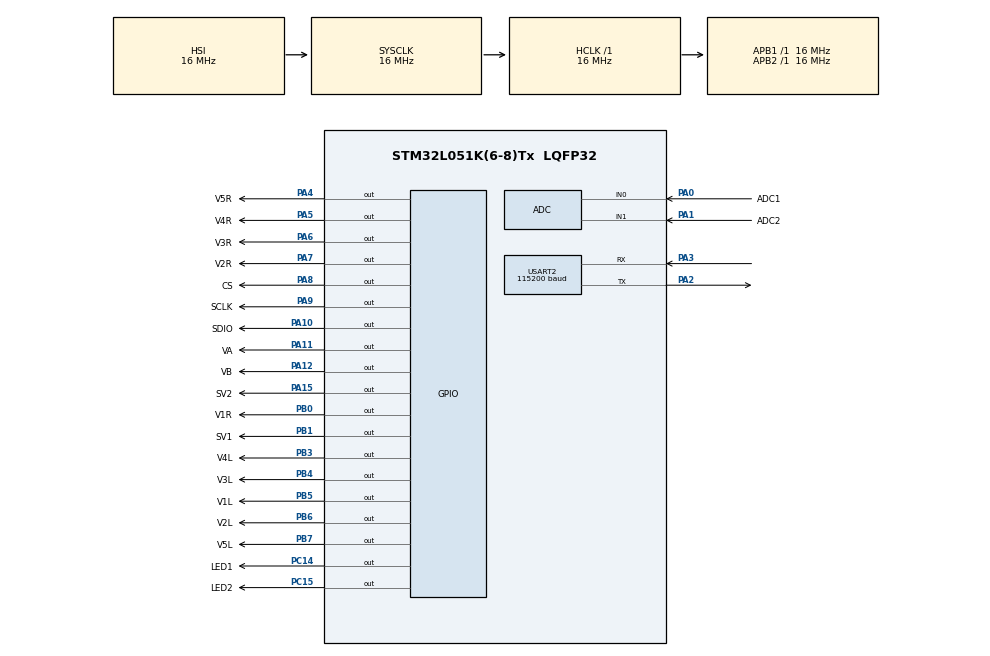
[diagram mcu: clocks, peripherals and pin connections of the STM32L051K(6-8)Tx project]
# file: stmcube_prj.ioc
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Mcu.Family=STM32L0
Mcu.Name=STM32L051K(6-8)Tx
Mcu.Package=LQFP32
NVIC.USART2_IRQn=true\:0\:0\:false\:false\:true\:true\:true
PA0.GPIO_Label=ADC1
PA0.Mode=IN0
PA0.Signal=ADC_IN0
PA1.GPIO_Label=ADC2
PA1.Mode=IN1
PA1.Signal=ADC_IN1
PA10.GPIO_Label=SDIO
PA10.Signal=GPIO_Output
PA11.GPIO_Label=VA
PA11.Signal=GPIO_Output
PA12.GPIO_Label=VB
PA12.Signal=GPIO_Output
PA13.Mode=Serial_Wire
PA13.Signal=SYS_SWDIO
PA14.Mode=Serial_Wire
PA14.Signal=SYS_SWCLK
PA15.GPIO_Label=SV2
PA15.Signal=GPIO_Output
PA2.Mode=Asynchronous
PA2.Signal=USART2_TX
PA3.Mode=Asynchronous
PA3.Signal=USART2_RX
PA4.GPIO_Label=V5R
PA4.Signal=GPIO_Output
PA5.GPIO_Label=V4R
PA5.Signal=GPIO_Output
PA6.GPIO_Label=V3R
PA6.Signal=GPIO_Output
PA7.GPIO_Label=V2R
PA7.Signal=GPIO_Output
PA8.GPIO_Label=CS
PA8.Signal=GPIO_Output
PA9.GPIO_Label=SCLK
PA9.Signal=GPIO_Output
PB0.GPIO_Label=V1R
PB0.Signal=GPIO_Output
PB1.GPIO_Label=SV1
PB1.Signal=GPIO_Output
PB3.GPIO_Label=V4L
PB3.Signal=GPIO_Output
PB4.GPIO_Label=V3L
PB4.Signal=GPIO_Output
PB5.GPIO_Label=V1L
PB5.Signal=GPIO_Output
PB6.GPIO_Label=V2L
PB6.Signal=GPIO_Output
PB7.GPIO_Label=V5L
PB7.Signal=GPIO_Output
PC14-OSC32_IN.GPIO_Label=LED1
PC14-OSC32_IN.Signal=GPIO_Output
PC15-OSC32_OUT.GPIO_Label=LED2
PC15-OSC32_OUT.Signal=GPIO_Output
ProjectManager.HeapSize=0x200
ProjectManager.StackSize=0x400
ProjectManager.TargetToolchain=TrueSTUDIO
RCC.AHBFreq_Value=16000000
RCC.APB1Freq_Value=16000000
RCC.APB1TimFreq_Value=16000000
RCC.APB2Freq_Value=16000000
RCC.APB2TimFreq_Value=16000000
RCC.HCLKFreq_Value=16000000
RCC.HSI16_VALUE=16000000
RCC.HSI_VALUE=16000000
RCC.LSE_VALUE=32768
RCC.MSI_VALUE=2097000
RCC.SYSCLKFreq_VALUE=16000000
RCC.SYSCLKSource=RCC_SYSCLKSOURCE_HSI
RCC.VCOOutputFreq_Value=48000000
USART2.BaudRate=115200
USART2.VirtualMode-Asynchronous=VM_ASYNC
board=custom

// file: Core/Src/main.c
/* USER CODE BEGIN Header */
/**
  ******************************************************************************
  * @file           : main.c
  * @brief          : Main program body
  ******************************************************************************
  * @attention
  *
  * <h2><center>&copy; Copyright (c) 2021 STMicroelectronics.
  * All rights reserved.</center></h2>
  *
  * This software component is licensed by ST under BSD 3-Clause license,
  * the "License"; You may not use this file except in compliance with the
  * License. You may obtain a copy of the License at:
  *                        opensource.org/licenses/BSD-3-Clause
  *
  ******************************************************************************
  */
/* USER CODE END Header */
#include "main.h"

/* USER CODE BEGIN PTD */
extern void handler_entry();
/* USER CODE END PTD */

ADC_HandleTypeDef hadc;

UART_HandleTypeDef huart2;

void SystemClock_Config(void);
static void MX_GPIO_Init(void);
static void MX_ADC_Init(void);
static void MX_USART2_UART_Init(void);

int main(void)
{

  /* MCU Configuration--------------------------------------------------------*/

  /* Reset of all peripherals, Initializes the Flash interface and the Systick. */
  HAL_Init();

  /* Configure the system clock */
  SystemClock_Config();

  /* Initialize all configured peripherals */
  MX_GPIO_Init();
  MX_ADC_Init();
  MX_USART2_UART_Init();

  /* Infinite loop */
  while (1)
  {

    /* USER CODE BEGIN 3 */
	  handler_entry();
  }
  /* USER CODE END 3 */
}

void SystemClock_Config(void)
{
  RCC_OscInitTypeDef RCC_OscInitStruct = {0};
  RCC_ClkInitTypeDef RCC_ClkInitStruct = {0};
  RCC_PeriphCLKInitTypeDef PeriphClkInit = {0};

  /** Configure the main internal regulator output voltage
  */
  __HAL_PWR_VOLTAGESCALING_CONFIG(PWR_REGULATOR_VOLTAGE_SCALE1);
  /** Initializes the RCC Oscillators according to the specified parameters
  * in the RCC_OscInitTypeDef structure.
  */
  RCC_OscInitStruct.OscillatorType = RCC_OSCILLATORTYPE_HSI;
  RCC_OscInitStruct.HSIState = RCC_HSI_ON;
  RCC_OscInitStruct.HSICalibrationValue = RCC_HSICALIBRATION_DEFAULT;
  RCC_OscInitStruct.PLL.PLLState = RCC_PLL_NONE;
  if (HAL_RCC_OscConfig(&RCC_OscInitStruct) != HAL_OK)
  {
    Error_Handler();
  }
  /** Initializes the CPU, AHB and APB buses clocks
  */
  RCC_ClkInitStruct.ClockType = RCC_CLOCKTYPE_HCLK|RCC_CLOCKTYPE_SYSCLK
                              |RCC_CLOCKTYPE_PCLK1|RCC_CLOCKTYPE_PCLK2;
  RCC_ClkInitStruct.SYSCLKSource = RCC_SYSCLKSOURCE_HSI;
  RCC_ClkInitStruct.AHBCLKDivider = RCC_SYSCLK_DIV1;
  RCC_ClkInitStruct.APB1CLKDivider = RCC_HCLK_DIV1;
  RCC_ClkInitStruct.APB2CLKDivider = RCC_HCLK_DIV1;

  if (HAL_RCC_ClockConfig(&RCC_ClkInitStruct, FLASH_LATENCY_0) != HAL_OK)
  {
    Error_Handler();
  }
  PeriphClkInit.PeriphClockSelection = RCC_PERIPHCLK_USART2;
  PeriphClkInit.Usart2ClockSelection = RCC_USART2CLKSOURCE_PCLK1;
  if (HAL_RCCEx_PeriphCLKConfig(&PeriphClkInit) != HAL_OK)
  {
    Error_Handler();
  }
}

static void MX_ADC_Init(void)
{

  ADC_ChannelConfTypeDef sConfig = {0};

  /** Configure the global features of the ADC (Clock, Resolution, Data Alignment and number of conversion)
  */
  hadc.Instance = ADC1;
  hadc.Init.OversamplingMode = DISABLE;
  hadc.Init.ClockPrescaler = ADC_CLOCK_SYNC_PCLK_DIV1;
  hadc.Init.Resolution = ADC_RESOLUTION_12B;
  hadc.Init.SamplingTime = ADC_SAMPLETIME_1CYCLE_5;
  hadc.Init.ScanConvMode = ADC_SCAN_DIRECTION_FORWARD;
  hadc.Init.DataAlign = ADC_DATAALIGN_RIGHT;
  hadc.Init.ContinuousConvMode = DISABLE;
  hadc.Init.DiscontinuousConvMode = DISABLE;
  hadc.Init.ExternalTrigConvEdge = ADC_EXTERNALTRIGCONVEDGE_NONE;
  hadc.Init.ExternalTrigConv = ADC_SOFTWARE_START;
  hadc.Init.DMAContinuousRequests = DISABLE;
  hadc.Init.EOCSelection = ADC_EOC_SINGLE_CONV;
  hadc.Init.Overrun = ADC_OVR_DATA_PRESERVED;
  hadc.Init.LowPowerAutoWait = DISABLE;
  hadc.Init.LowPowerFrequencyMode = DISABLE;
  hadc.Init.LowPowerAutoPowerOff = DISABLE;
  if (HAL_ADC_Init(&hadc) != HAL_OK)
  {
    Error_Handler();
  }
  /** Configure for the selected ADC regular channel to be converted.
  */
  sConfig.Channel = ADC_CHANNEL_0;
  sConfig.Rank = ADC_RANK_CHANNEL_NUMBER;
  if (HAL_ADC_ConfigChannel(&hadc, &sConfig) != HAL_OK)
  {
    Error_Handler();
  }
  /** Configure for the selected ADC regular channel to be converted.
  */
  sConfig.Channel = ADC_CHANNEL_1;
  if (HAL_ADC_ConfigChannel(&hadc, &sConfig) != HAL_OK)
  {
    Error_Handler();
  }

}

static void MX_USART2_UART_Init(void)
{

  huart2.Instance = USART2;
  huart2.Init.BaudRate = 115200;
  huart2.Init.WordLength = UART_WORDLENGTH_8B;
  huart2.Init.StopBits = UART_STOPBITS_1;
  huart2.Init.Parity = UART_PARITY_NONE;
  huart2.Init.Mode = UART_MODE_TX_RX;
  huart2.Init.HwFlowCtl = UART_HWCONTROL_NONE;
  huart2.Init.OverSampling = UART_OVERSAMPLING_16;
  huart2.Init.OneBitSampling = UART_ONE_BIT_SAMPLE_DISABLE;
  huart2.AdvancedInit.AdvFeatureInit = UART_ADVFEATURE_NO_INIT;
  if (HAL_UART_Init(&huart2) != HAL_OK)
  {
    Error_Handler();
  }

}

static void MX_GPIO_Init(void)
{
  GPIO_InitTypeDef GPIO_InitStruct = {0};

  /* GPIO Ports Clock Enable */
  __HAL_RCC_GPIOC_CLK_ENABLE();
  __HAL_RCC_GPIOA_CLK_ENABLE();
  __HAL_RCC_GPIOB_CLK_ENABLE();

  /*Configure GPIO pin Output Level */
  HAL_GPIO_WritePin(GPIOC, LED1_Pin|LED2_Pin, GPIO_PIN_RESET);

  /*Configure GPIO pin Output Level */
  HAL_GPIO_WritePin(GPIOA, V5R_Pin|V4R_Pin|V3R_Pin|V2R_Pin
                          |CS_Pin|SCLK_Pin|SDIO_Pin|VA_Pin
                          |VB_Pin|SV2_Pin, GPIO_PIN_RESET);

  /*Configure GPIO pin Output Level */
  HAL_GPIO_WritePin(GPIOB, V1R_Pin|SV1_Pin|V4L_Pin|V3L_Pin
                          |V1L_Pin|V2L_Pin|V5L_Pin, GPIO_PIN_RESET);

  /*Configure GPIO pins : LED1_Pin LED2_Pin */
  GPIO_InitStruct.Pin = LED1_Pin|LED2_Pin;
  GPIO_InitStruct.Mode = GPIO_MODE_OUTPUT_PP;
  GPIO_InitStruct.Pull = GPIO_NOPULL;
  GPIO_InitStruct.Speed = GPIO_SPEED_FREQ_LOW;
  HAL_GPIO_Init(GPIOC, &GPIO_InitStruct);

  /*Configure GPIO pins : V5R_Pin V4R_Pin V3R_Pin V2R_Pin
                           CS_Pin SCLK_Pin SDIO_Pin VA_Pin
                           VB_Pin SV2_Pin */
  GPIO_InitStruct.Pin = V5R_Pin|V4R_Pin|V3R_Pin|V2R_Pin
                          |CS_Pin|SCLK_Pin|SDIO_Pin|VA_Pin
                          |VB_Pin|SV2_Pin;
  GPIO_InitStruct.Mode = GPIO_MODE_OUTPUT_PP;
  GPIO_InitStruct.Pull = GPIO_NOPULL;
  GPIO_InitStruct.Speed = GPIO_SPEED_FREQ_LOW;
  HAL_GPIO_Init(GPIOA, &GPIO_InitStruct);

  /*Configure GPIO pins : V1R_Pin SV1_Pin V4L_Pin V3L_Pin
                           V1L_Pin V2L_Pin V5L_Pin */
  GPIO_InitStruct.Pin = V1R_Pin|SV1_Pin|V4L_Pin|V3L_Pin
                          |V1L_Pin|V2L_Pin|V5L_Pin;
  GPIO_InitStruct.Mode = GPIO_MODE_OUTPUT_PP;
  GPIO_InitStruct.Pull = GPIO_NOPULL;
  GPIO_InitStruct.Speed = GPIO_SPEED_FREQ_LOW;
  HAL_GPIO_Init(GPIOB, &GPIO_InitStruct);

}

void Error_Handler(void)
{
  __disable_irq();
  while (1)
  {
  }
}

/************************ (C) COPYRIGHT STMicroelectronics *****END OF FILE****/
